AUTOSAR XML (schema 00048)
package /HuaweiMDC/FunctionalSoftware/TrafficLightDetectionApplication/Execution
  executable TrafficLightDetectionExecutable
    root sw component prototype TrafficLightDetectionRootSwComponent: application-type=TrafficLightDetectionApplicationSwComponent
package /HuaweiMDC/FunctionalSoftware/TrafficLightDetectionApplication/SwComponent
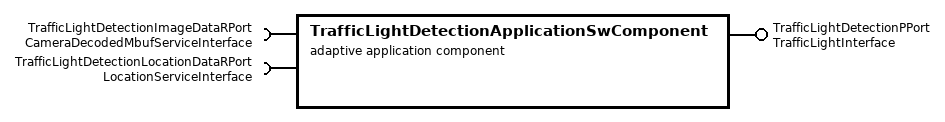
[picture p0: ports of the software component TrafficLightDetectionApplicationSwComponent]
  adaptive application sw component type TrafficLightDetectionApplicationSwComponent
    require port TrafficLightDetectionImageDataRPort: required-interface=CameraDecodedMbufServiceInterface
    provide port TrafficLightDetectionPPort: provided-interface=TrafficLightInterface
    require port TrafficLightDetectionLocationDataRPort: required-interface=LocationServiceInterface
